# STM32H723VEH6 register map
File version: 1.0
Registers are 32-bit, access not given, reset 0x0 unless marked. A register's access mark holds for its fields unless they carry their own. Offsets are from the block's base; [hi:lo] are bit positions; {n}, {i} and the like mark numbered series; 'fields as' and 'values as' point back to an identical list.

## FLASH
Base 0x52002000
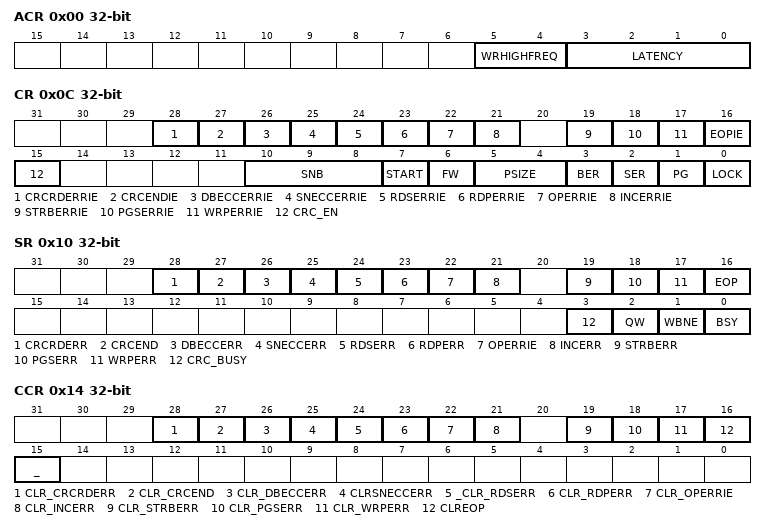
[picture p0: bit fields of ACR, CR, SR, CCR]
0x00 ACR
  [5:4] WRHIGHFREQ, [3:0] LATENCY
0x04 KEYR
  [31:0] KEYKEYRR
0x08 OPTKEYR
0x0C CR
  [28] CRCRDERRIE, [27] CRCENDIE, [26] DBECCERRIE, [25] SNECCERRIE, [24] RDSERRIE, [23] RDPERRIE, [22] OPERRIE, [21] INCERRIE, [19] STRBERRIE, [18] PGSERRIE, [17] WRPERRIE, [16] EOPIE, [15] CRC_EN, [10:8] SNB, [7] START, [6] FW, [5:4] PSIZE, [3] BER, [2] SER, [1] PG, [0] LOCK
0x10 SR
  [28] CRCRDERR, [27] CRCEND, [26] DBECCERR, [25] SNECCERR, [24] RDSERR, [23] RDPERR, [22] OPERRIE, [21] INCERR, [19] STRBERR, [18] PGSERR, [17] WRPERR, [16] EOP, [3] CRC_BUSY, [2] QW, [1] WBNE, [0] BSY
0x14 CCR
  [28] CLR_CRCRDERR, [27] CLR_CRCEND, [26] CLR_DBECCERR, [25] CLRSNECCERR, [24] _CLR_RDSERR, [23] CLR_RDPERR, [22] CLR_OPERRIE, [21] CLR_INCERR, [19] CLR_STRBERR, [18] CLR_PGSERR, [17] CLR_WRPERR, [16] CLREOP, [15] _
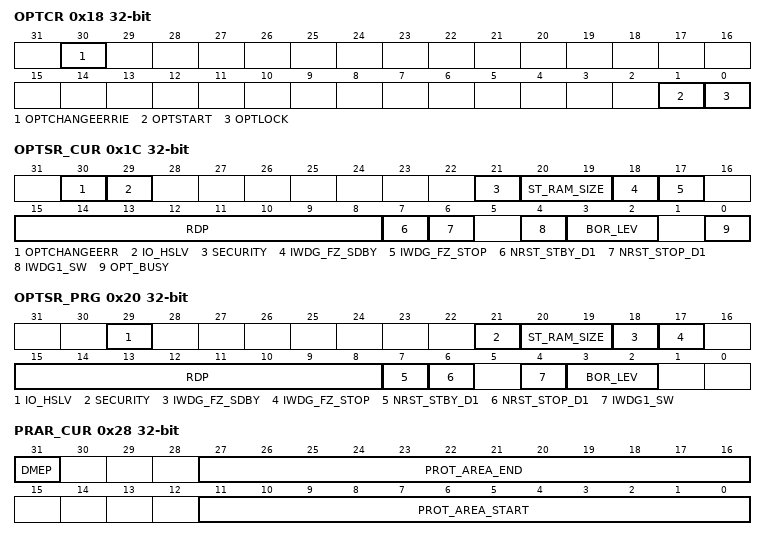
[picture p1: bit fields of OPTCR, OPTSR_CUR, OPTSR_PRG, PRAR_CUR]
0x18 OPTCR
  [30] OPTCHANGEERRIE, [1] OPTSTART, [0] OPTLOCK
0x1C OPTSR_CUR
  [30] OPTCHANGEERR, [29] IO_HSLV, [21] SECURITY, [20:19] ST_RAM_SIZE, [18] IWDG_FZ_SDBY, [17] IWDG_FZ_STOP, [15:8] RDP, [7] NRST_STBY_D1, [6] NRST_STOP_D1, [4] IWDG1_SW, [3:2] BOR_LEV, [0] OPT_BUSY
0x20 OPTSR_PRG
  [29] IO_HSLV, [21] SECURITY, [20:19] ST_RAM_SIZE, [18] IWDG_FZ_SDBY, [17] IWDG_FZ_STOP, [15:8] RDP, [7] NRST_STBY_D1, [6] NRST_STOP_D1, [4] IWDG1_SW, [3:2] BOR_LEV
0x24 OPTCCR
  [30] CLR_OPTCHANGEERR
0x28 PRAR_CUR
  [31] DMEP, [27:16] PROT_AREA_END, [11:0] PROT_AREA_START
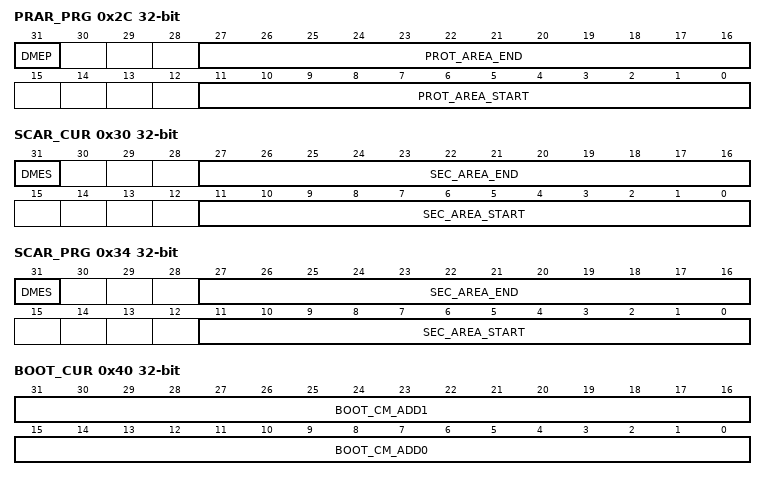
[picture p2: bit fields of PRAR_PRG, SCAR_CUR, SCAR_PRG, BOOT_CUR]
0x2C PRAR_PRG
  [31] DMEP, [27:16] PROT_AREA_END, [11:0] PROT_AREA_START
0x30 SCAR_CUR
  [31] DMES, [27:16] SEC_AREA_END, [11:0] SEC_AREA_START
0x34 SCAR_PRG
  [31] DMES, [27:16] SEC_AREA_END, [11:0] SEC_AREA_START
0x38 WPSN_CUR
  [7:0] WRPSn
0x3C WPSN_PRG
  [7:0] WRPSn
0x40 BOOT_CUR
  [31:16] BOOT_CM_ADD1, [15:0] BOOT_CM_ADD0
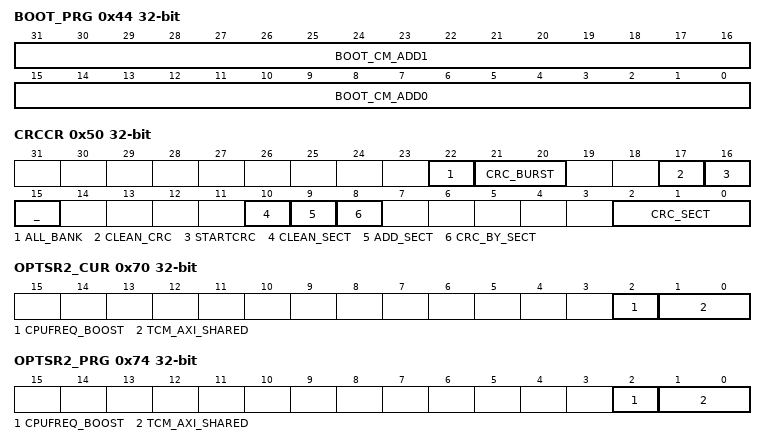
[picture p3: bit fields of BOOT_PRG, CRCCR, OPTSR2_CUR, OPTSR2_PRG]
0x44 BOOT_PRG
  [31:16] BOOT_CM_ADD1, [15:0] BOOT_CM_ADD0
0x50 CRCCR
  [22] ALL_BANK, [21:20] CRC_BURST, [17] CLEAN_CRC, [16] STARTCRC, [15] _, [10] CLEAN_SECT, [9] ADD_SECT, [8] CRC_BY_SECT, [2:0] CRC_SECT
0x54 CRCSADDR
  [19:2] CRC_START_ADDR
0x58 CRCEADDR
  [19:2] CRC_END_ADDR
0x5C CRCDATAR
  [31:0] CRC_DATA
0x60 ECC_FAR
  [14:0] FAIL_ECC_ADDR
0x70 OPTSR2_CUR
  [2] CPUFREQ_BOOST, [1:0] TCM_AXI_SHARED
0x74 OPTSR2_PRG
  [2] CPUFREQ_BOOST, [1:0] TCM_AXI_SHARED

## FMC
Base 0x52004000
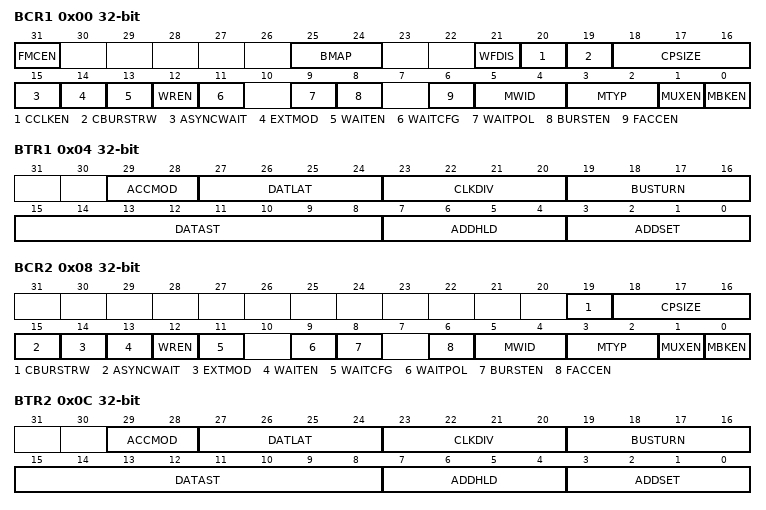
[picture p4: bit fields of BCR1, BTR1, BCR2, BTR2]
0x00 BCR1
  [31] FMCEN, [25:24] BMAP, [21] WFDIS, [20] CCLKEN, [19] CBURSTRW, [18:16] CPSIZE, [15] ASYNCWAIT, [14] EXTMOD, [13] WAITEN, [12] WREN, [11] WAITCFG, [9] WAITPOL, [8] BURSTEN, [6] FACCEN, [5:4] MWID, [3:2] MTYP, [1] MUXEN, [0] MBKEN
0x04 BTR1
  [29:28] ACCMOD, [27:24] DATLAT, [23:20] CLKDIV, [19:16] BUSTURN, [15:8] DATAST, [7:4] ADDHLD, [3:0] ADDSET
0x08 BCR2
  [19] CBURSTRW, [18:16] CPSIZE, [15] ASYNCWAIT, [14] EXTMOD, [13] WAITEN, [12] WREN, [11] WAITCFG, [9] WAITPOL, [8] BURSTEN, [6] FACCEN, [5:4] MWID, [3:2] MTYP, [1] MUXEN, [0] MBKEN
0x0C BTR2
  fields as BTR1
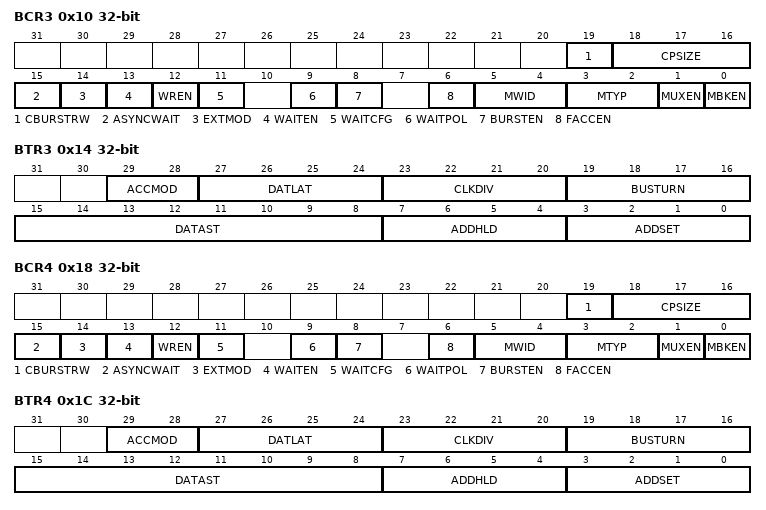
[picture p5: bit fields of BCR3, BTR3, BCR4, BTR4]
0x10 BCR3
  fields as BCR2
0x14 BTR3
  fields as BTR1
0x18 BCR4
  fields as BCR2
0x1C BTR4
  fields as BTR1
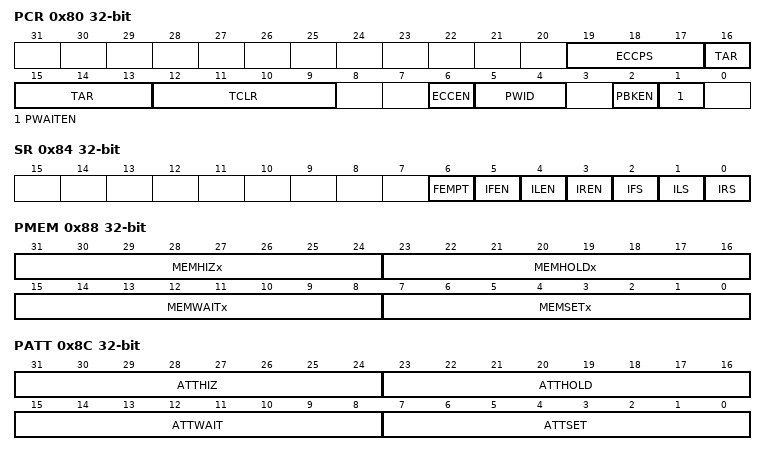
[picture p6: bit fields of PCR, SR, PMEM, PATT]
0x80 PCR
  [19:17] ECCPS, [16:13] TAR, [12:9] TCLR, [6] ECCEN, [5:4] PWID, [2] PBKEN, [1] PWAITEN
0x84 SR
  [6] FEMPT, [5] IFEN, [4] ILEN, [3] IREN, [2] IFS, [1] ILS, [0] IRS
0x88 PMEM
  [31:24] MEMHIZx, [23:16] MEMHOLDx, [15:8] MEMWAITx, [7:0] MEMSETx
0x8C PATT
  [31:24] ATTHIZ, [23:16] ATTHOLD, [15:8] ATTWAIT, [7:0] ATTSET
0x94 ECCR
  [31:0] ECC
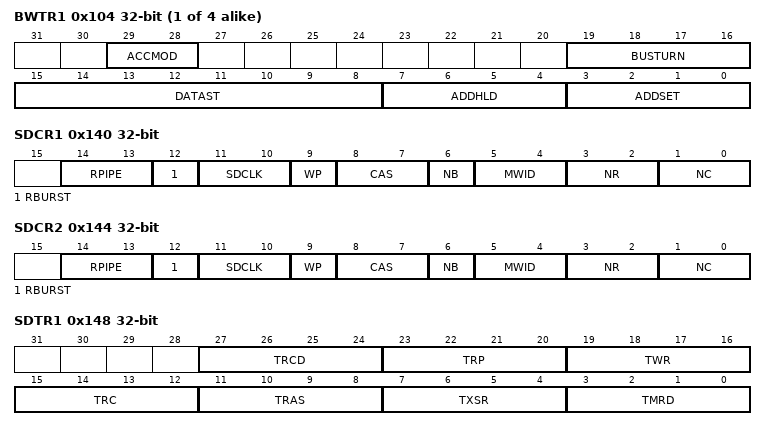
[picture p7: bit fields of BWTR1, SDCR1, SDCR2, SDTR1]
{0xFC+8i} BWTR{i} (i=1..4)
  [29:28] ACCMOD, [19:16] BUSTURN, [15:8] DATAST, [7:4] ADDHLD, [3:0] ADDSET
0x140 SDCR1
  [14:13] RPIPE, [12] RBURST, [11:10] SDCLK, [9] WP, [8:7] CAS, [6] NB, [5:4] MWID, [3:2] NR, [1:0] NC
0x144 SDCR2
  fields as SDCR1
0x148 SDTR1
  [27:24] TRCD, [23:20] TRP, [19:16] TWR, [15:12] TRC, [11:8] TRAS, [7:4] TXSR, [3:0] TMRD
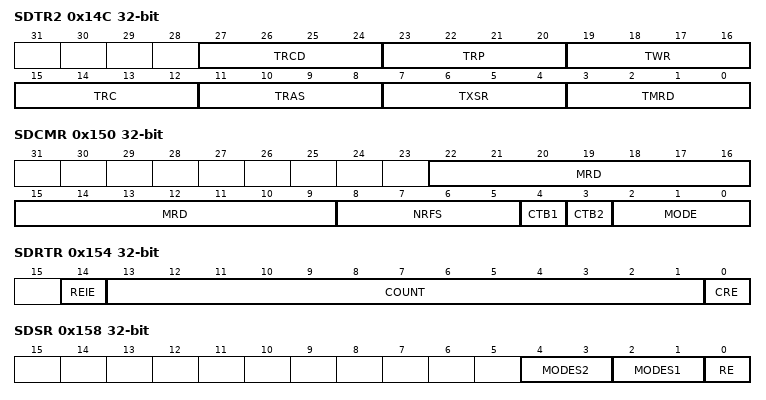
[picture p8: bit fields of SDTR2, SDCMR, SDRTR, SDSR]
0x14C SDTR2
  fields as SDTR1
0x150 SDCMR
  [22:9] MRD, [8:5] NRFS, [4] CTB1, [3] CTB2, [2:0] MODE
0x154 SDRTR
  [14] REIE, [13:1] COUNT, [0] CRE
0x158 SDSR
  [4:3] MODES2, [2:1] MODES1, [0] RE
